# cslr_sys_001 register map
Vendor: Texas Instruments
Peripheral module from a debugger description file (folder C5505).
Address unit: 16 bits
Registers are 16-bit, access not given, reset 0x0 unless marked. A register's access mark holds for its fields unless they carry their own. Offsets are as the file gives them; lines under a group give offsets from that group; [hi:lo] are bit positions; {n}, {i} and the like mark numbered series; 'fields as' and 'values as' point back to an identical list; <NAME> marks a mode.

## SYS — The DSP system module controls several features of the DSP, e.g. clock control, DMA event synchronization, PLL settings, and the CLKOUT source.
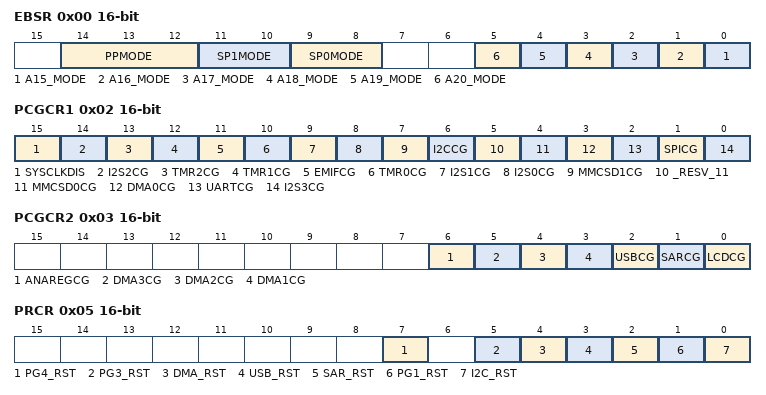
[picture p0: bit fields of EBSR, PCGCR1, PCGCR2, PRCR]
0x00 EBSR — External Bus Selection Register
  [14:12] PPMODE rw — Parallel port mode bits. These bits control the pin muxing on the parallel port.
    {v}=MODE{v} (v=0..6); 7=MODE7 (Reserved, do not use.)
  [11:10] SP1MODE rw — Serial port 1 mode bits. These bits control the pin muxing on serial port 1.
    {v}=MODE{v} (v=0..3)
  [9:8] SP0MODE rw — Serial port 0 mode bits. These bits control the pin muxing on serial port 0.
    {v}=MODE{v} (v=0..3)
  [n-15] A{n}_MODE rw (n=15..20) — This bit controls the pin multiplexing on EM_A[{n}].
    0=MODE0 (Pin behaves as EM_A[{n}].); 1=MODE1 (Pin behaves as GP[{n+6}].)
0x02 PCGCR1 — Peripheral Clock Gating Configuration Register 1
  [15] SYSCLKDIS rw — System clock disable bit. This bit can be used to turn off the system clock. Setting the WAKEUP pin high enables the system clock. Since the WAKEUP pin is used to re-enable the system clock, the WAKEUP pin must be low to disable the system clock.
    0=ACTIVE (System clock is active.); 1=DISABLED (System clock is disabled.)
  [14] I2S2CG rw — I2S2 clock gate control bit. This bit is used to enable and disable the I2S2 peripheral clock.
    0=ACTIVE (Peripheral clock is active.); 1=DISABLED (Peripheral clock is disabled.)
  [13] TMR2CG rw — Timer 2 clock gate control bit. This bit is used to enable and disable the Timer 2 peripheral clock.
    values as I2S2CG
  [12] TMR1CG rw — Timer 1 clock gate control bit. This bit is used to enable and disable the Timer 1 peripheral clock.
    values as I2S2CG
  [11] EMIFCG rw — EMIF clock gate control bit. This bit is used to enable and disable the EMIF peripheral clock. NOTE: You must request permission before stopping the EMIF clock through the peripheral clock stop request/acknowledge register (CLKSTOP).
    values as I2S2CG
  [10] TMR0CG rw — Timer 0 clock gate control bit. This bit is used to enable and disable the Timer 0 peripheral clock.
    values as I2S2CG
  [9] I2S1CG rw — I2S1 clock gate control bit. This bit is used to enable and disable the I2S1 peripheral clock.
    values as I2S2CG
  [8] I2S0CG rw — I2S0 clock gate control bit. This bit is used to enable and disable the I2S0 peripheral clock.
    values as I2S2CG
  [7] MMCSD1CG rw — MMC/SD1 clock gate control bit. This bit is used to enable and disable the MMC/SD1 peripheral clock.
    values as I2S2CG
  [6] I2CCG rw — I2C clock gate control bit. This bit is used to enable and disable the I2C peripheral clock.
    values as I2S2CG
  [5] _RESV_11 — Reserved, you must always write 1 to this bit. (access N)
  [4] MMCSD0CG rw — MMC/SD0 clock gate control bit. This bit is used to enable and disable the MMC/SD0 peripheral clock.
    values as I2S2CG
  [3] DMA0CG rw — DMA controller 0 clock gate control bit. This bit is used to enable and disable the peripheral clock the DMA controller 0.
    values as I2S2CG
  [2] UARTCG rw — UART clock gate control bit. This bit is used to enable and disable the UART peripheral clock. NOTE: You must request permission before stopping the UART clock through the peripheral clock stop request/acknowledge register (CLKSTOP).
    values as I2S2CG
  [1] SPICG rw — SPI clock gate control bit. This bit is used to enable and disable the SPI controller peripheral clock.
    values as I2S2CG
  [0] I2S3CG rw — I2S3 clock gate control bit. This bit is used to enable and disable the I2S3 peripheral clock.
    values as I2S2CG
0x03 PCGCR2 — Peripheral Clock Gating Configuration Register 2
  [6] ANAREGCG rw — Analog registers clock gate control bit. This bit is used to enable and disable the clock to the registers that control the analog domain of the device, i.e. registers in the 7000h-70FFh I/O space address range. NOTE: When SARCG = 0, the clocks to the analog domain registers is enabled regardless of the ANAREGCG setting.
    0=ACTIVE (Clock is active.); 1=DISABLED (Clock is disabled.)
  [5] DMA3CG rw — DMA controller 3 clock gate control bit. This bit is used to enable and disable the peripheral clock the DMA controller 3.
    values as PCGCR1.I2S2CG
  [4] DMA2CG rw — DMA controller 2 clock gate control bit. This bit is used to enable and disable the peripheral clock the DMA controller 2.
    values as PCGCR1.I2S2CG
  [3] DMA1CG rw — DMA controller 1 clock gate control bit. This bit is used to enable and disable the peripheral clock the DMA controller 1.
    values as PCGCR1.I2S2CG
  [2] USBCG rw — USB clock gate control bit. This bit is used to enable and disable the peripheral clock the USB. NOTE: You must request permission before stopping the USB clock through the peripheral clock stop request/acknowledge register (CLKSTOP).
    values as PCGCR1.I2S2CG
  [1] SARCG rw — SAR clock gate control bit. This bit is used to enable and disable the SAR peripheral clock. NOTE: When SARCG = 0, the clocks to the analog domain registers is enabled regardless of the ANAREGCG setting.
    values as PCGCR1.I2S2CG
  [0] LCDCG rw — LCD controller clock gate control bit. This bit is used to enable and disable the LCD controller peripheral clock.
    values as PCGCR1.I2S2CG
0x04 PSRCR rw — Peripheral Software Reset Counter Register
  [15:0] COUNT — Count bits. These bits specify the number of system clock (SYSCLK) cycles the software reset bits are asserted. When the software counter reaches 0, the software reset bits will be cleared to 0. Always initialize this field with 20h.
0x05 PRCR — Peripheral Reset Control Register
  [7] PG4_RST rw — Peripheral group 4 software reset bit. Drives the LCD, I2S2, I2S3, UART, and SPI reset signal.
    0=RST (Reset deasserted, modules out of reset.); 1=NRST (Reset asserted, modules in reset.)
  [5] PG3_RST rw — Peripheral group 3 software reset bit. Drives the MMC/SD0, MMC/SD1, I2S0, and I2S1 reset signal.
    values as PG4_RST
  [4] DMA_RST rw — DMA software reset bit. Drives the reset signal to the DMA controllers.
    values as PG4_RST
  [3] USB_RST rw — USB software reset bit. Drives the USB reset signal.
    0=RST (Reset deasserted, module out of reset.); 1=NRST (Reset asserted, module in reset.)
  [2] SAR_RST rw — Reserved. Always write 0 to these bits.
    values as USB_RST
  [1] PG1_RST rw — Peripheral group 1 software reset bit. Drives the EMIF and timers reset signal.
    values as PG4_RST
  [0] I2C_RST rw — I2C software reset bit. Drives the I2C reset signal.
    values as USB_RST
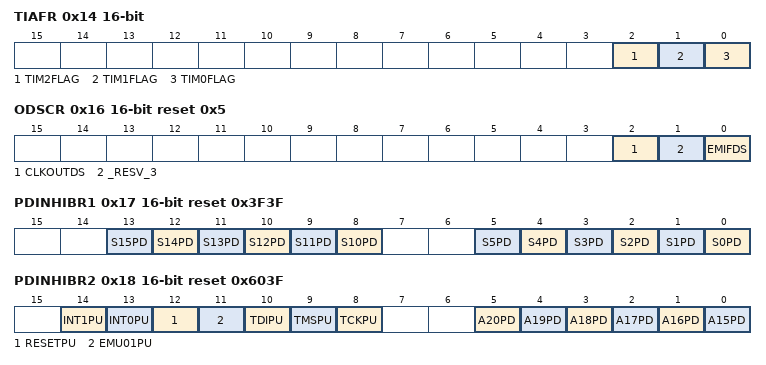
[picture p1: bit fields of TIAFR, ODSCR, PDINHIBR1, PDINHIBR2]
0x14 TIAFR — Timer Interrupt Aggregation Flag Register
  [all] fields
    0=NOINT (Timer has not generated an interrupt.); 1=INT (Timer interrupt has occurred.)
  [2] TIM2FLAG — Timer 2 interrupt flag bit. This bit latches the timer interrupt signal when the timer counter expires. You can clear this flag bit by writing a 1 to it. (access RW1C)
  [1] TIM1FLAG — Timer 1 interrupt flag bit. This bit latches the timer interrupt signal when the timer counter expires. You can clear this flag bit by writing a 1 to it. (access RW1C)
  [0] TIM0FLAG — Timer 0 interrupt flag bit. This bit latches the timer interrupt signal when the timer counter expires. You can clear this flag bit by writing a 1 to it. (access RW1C)
0x16 ODSCR reset 0x5 — Output Drive Strength Control Register
  [2] CLKOUTDS rw — CLKOUT pin output drive strength bits. These bits set the drive strength for the CLKOUT pin.
    0=MIN (Minimum drive strength.); 1=MAX (Maximum drive strength.)
  [1] _RESV_3 — (access N)
  [0] EMIFDS rw — EMIF pin output drive strength bits. These bits set the drive strength for the EMIF pins.
    values as CLKOUTDS
0x17 PDINHIBR1 reset 0x3F3F — Pull-Down Inhibit Register 1
  [all] fields
    0=ENABLE (Pin pull-down is enabled.); 1=DISABLE (Pin pull-down is disabled.)
  [n-2] S{n}PD rw (n=10..15) — Serial port pin {n} pull-down inhibit bit. Setting this bit to 1 disables the pin internal pull-down.
  [n] S{n}PD rw (n=0..5) — Serial port pin {n} pull-down inhibit bit. Setting this bit to 1 disables the pin internal pull-down.
0x18 PDINHIBR2 reset 0x603F — Pull-Down Inhibit Register 2
  [14] INT1PU rw — Interrupt 1 pin pull-up inhibit bit. Setting this bit to 1 disables the pin internal pull-up.
    0=ENABLE (Pin pull-up is enabled.); 1=DISABLE (Pin pull-up is disabled.)
  [13] INT0PU rw — Interrupt 0 pin pull-up inhibit bit. Setting this bit to 1 disables the pin internal pull-up.
    values as INT1PU
  [12] RESETPU rw — Reset pin pull-up inhibit bit. Setting this bit to 1 disables the pin internal pull-up.
    values as INT1PU
  [11] EMU01PU rw — EMU1 and EMU0 pin pull-up inhibit bit. Setting this bit to 1 disables the pin internal pull-up.
    values as INT1PU
  [10] TDIPU rw — TDI pin pull-up inhibit bit. Setting this bit to 1 disables the pin internal pull-up.
    values as INT1PU
  [9] TMSPU rw — TMS pin pull-up inhibit bit. Setting this bit to 1 disables the pin internal pull-up.
    values as INT1PU
  [8] TCKPU ro — TCK pin pull-up inhibit bit. Setting this bit to 1 disables the pin internal pull-up.
    values as INT1PU
  [n-15] A{n}PD rw (n=15..20) — EMIF A[{n}] pin pull-down inhibit bit. Setting this bit to 1 disables the pin internal pull-down.
    values as the fields of PDINHIBR1
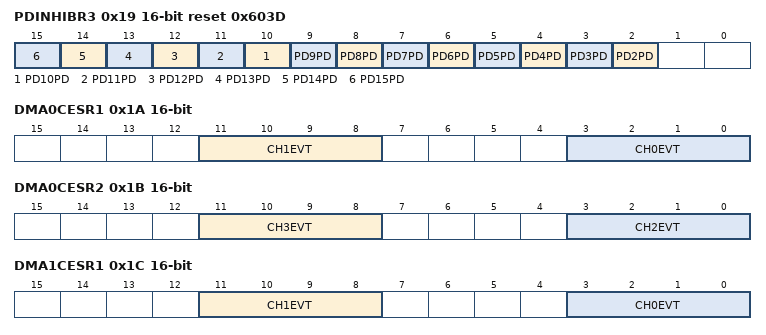
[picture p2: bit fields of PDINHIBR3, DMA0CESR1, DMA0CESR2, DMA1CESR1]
0x19 PDINHIBR3 reset 0x603D — Pull-Down Inhibit Register 3
  [all] fields
    values as the fields of PDINHIBR1
  [n] PD{n}PD rw (n=2..15) — Parallel port {n} pin pull-down inhibit bit. Setting this bit to 1 disables the pin internal pull-down.
0x1A DMA0CESR1 — Defines the synchronization events for DMA0 channel 1 and 0.
  [11:8] CH1EVT rw — Channel 1 synchronization events. When SYNCMODE = 1 in the channel DMATCR2, the CH1EVT bits in the DMAnCESR registers specify the synchronization event for activity in the DMA controller.
  [3:0] CH0EVT rw — Channel 0 synchronization events. When SYNCMODE = 1 in the channel DMATCR2, the CH0EVT bits in the DMAnCESR registers specify the synchronization event for activity in the DMA controller.
0x1B DMA0CESR2 — Defines the synchronization events for DMA0 channel 3 and 2.
  [11:8] CH3EVT rw — Channel 3 synchronization events. When SYNCMODE = 1 in the channel DMATCR2, the CH3EVT bits in the DMAnCESR registers specify the synchronization event for activity in the DMA controller.
  [3:0] CH2EVT rw — Channel 2 synchronization events. When SYNCMODE = 1 in the channel DMATCR2, the CH2EVT bits in the DMAnCESR registers specify the synchronization event for activity in the DMA controller.
0x1C DMA1CESR1 — Defines the synchronization events for DMA1 channel 1 and 0.
  fields as DMA0CESR1
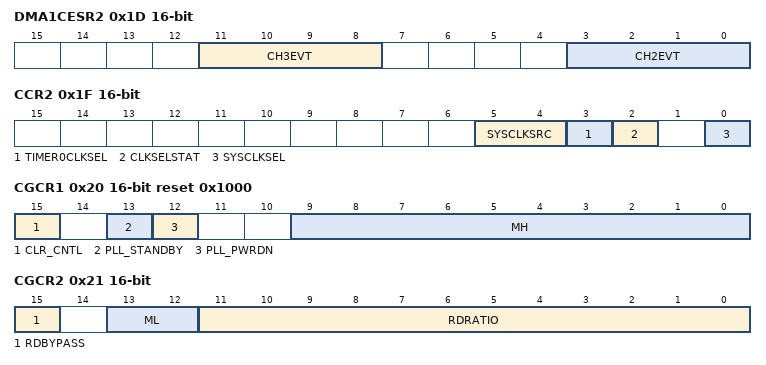
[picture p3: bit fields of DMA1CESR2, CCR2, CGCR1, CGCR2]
0x1D DMA1CESR2 — Defines the synchronization events for DMA1 channel 3 and 2.
  fields as DMA0CESR2
0x1E CCR1 — Clock Configuration Register 1
0x1E SDRAMCCR reset 0x1 — SDRAM Clock Control Register
  [0] SDCLK_EN rw — SDRAM Clock Control 0 = SDCLK on. 1 = SDCLK off.
    0=SDCLKon (SDRAM clock is on.); 1=SDCLKoff (SDRAM clock is off.)
0x1F CCR2 — Clock Configuration Register 2
  [5:4] SYSCLKSRC ro — System clock source bits. These read-only bits reflect the source for the system clock.
  [3] TIMER0CLKSEL ro — Timer0 clock source select bit. This bit specifies the input clock to Timer0.
    0=SYSCLK (Timer0 uses SYSCLK as input clock.); 1=PLLOUT (Timer0 uses PLL output clock (PLLOUT) as input clock.)
  [2] CLKSELSTAT ro — CLK_SEL pin status bit. This reflects the state of the CLK_SEL pin.
    0=RTCIN (CLK_SEL pin is low (RTC input clock selected).); 1=CLKIN (CLK_SEL pin is high (CLKIN input clock selected.))
  [0] SYSCLKSEL rw — System clock source select bit. This bit is used to select between the two main clocking modes for the DSP: bypass and lock mode. In bypass mode, the DSP clock generator is byassed and the system clock is set to either CLKIN or the RTC output (as determined by the CLKSEL pin). In lock mode, the system clock is set to the output of the DSP clock generator. Logic in the system clock generator prevents switching from bypass mode to lock mode if the PLL is powered down. After settings SYSCLKSEL = 1, you can check the SYSCLKSRC bits to determine if the system clock generator is in lock mode.
    0=BYPASS (Bypass mode is selected.); 1=LOCK (Lock mode is selected.)
0x20 CGCR1 reset 0x1000 — Clock Generator Control Register 1
  [15] CLR_CNTL rw — Clear control bit. This bit is used to clear digital flip flops within the clock generator. This bit must be cleared to 0 while changing the PLL settings.
    0=CLEAR (Digital flip-flops cleared.); 1=SET (Digital flip-flops not cleard (normal operation).)
  [13] PLL_STANDBY rw — PLL standby bit. This bit is used to place the PLL in standy mode. This bit is used for test purposes only and must always be cleared to 0.
    0=ACTIVE (PLL is active (normal operation).); 1=STANDBY (PLL is in standby mode.)
  [12] PLL_PWRDN rw — PLL power down bit. This bit is used to power down the PLL when it is not being used.
    0=POWERED (PLL is powered up.); 1=POWERDWN (PLL is powered down.)
  [9:0] MH rw — PLL multiplier value bits. These bits along with the ML bits in CGCR2 define the PLL multipler value. Multiplier value = MH x 4 + ML + 4. For example, MH = 23Bh and ML = 1h means multiply by 2289 (8F1h).
0x21 CGCR2 — Clock Generator Control Register 2
  [15] RDBYPASS rw — Reference divider bypass bit. When this bit is set to 1 the reference divider in the DSP clock generator is bypassed. When this bit is set to 0, the reference clock to the DSP clock generator is divided by the reference divider. The RD bits specify the divider value.
    0=ENABLE (Use the reference divider.); 1=BYPASS (Bypass the reference divider.)
  [13:12] ML rw — PLL multiplier value bits. These bits along with the MH bits in CGCR1 define the PLL multipler value. Multiplier value = MH x 4 + ML + 4. For example, MH = 23Bh and ML = 1h means multiply by 2289 (8F1h).
  [11:0] RDRATIO rw — Divider ratio bits for the reference divider. Divider value = RD_DIV + 4. For example, setting RD_DIV = 0 means divide by 4.
0x22 CGCR3 rw reset 0x806 — Clock Generator Control Register 3
  [15:0] INIT — Initialization bits for DSP clock generator. These bits must initialized with a pre-determined value during PLL configuration.
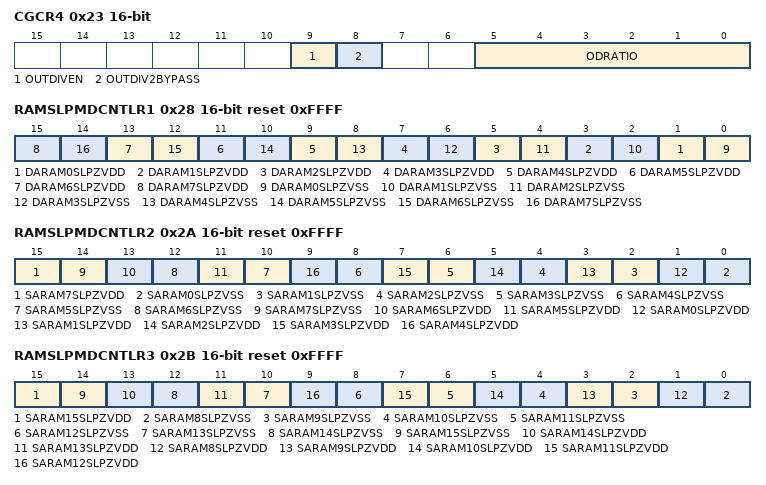
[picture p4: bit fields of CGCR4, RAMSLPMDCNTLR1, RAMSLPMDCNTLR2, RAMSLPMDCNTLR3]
0x23 CGCR4 — Clock Generator Control Register 4
  [9] OUTDIVEN rw — Output divider and fixed /2 divider enable bit. This bit determines whether the output divider and the fixed /2 divider are enabled or bypassed.
    0=BYPASS (The output divider and the fixed /2 divider are bypassed.); 1=ENABLE (The output divider and the fixed /2 divider are enabled.)
  [8] OUTDIV2BYPASS rw — Output divider bypass bit. This bit determines whether the output divider is bypassed. The fixed /2 divider is used regardless of the setting of this bit.
    0=ENABLE (The output divider is bypassed.); 1=BYPASS (The output divider is enabled.)
  [5:0] ODRATIO rw — Divider ratio bits for the output divider. Divider value = ODRATIO + 4. For example, setting ODRATIO = 2 means divide by 6. NOTE: The divider output is further divided by the fixed /2 divider.
0x24 CCSSR reset 0xB — CLKOUT Clock Source Register
  [3:0] SRC rw — CLKOUT source bits. These bits specify the source clock for the CLKOUT pin.
0x26 ECDR reset 0x1 — EMIF Clock Divider Register
  [0] EDIV rw — EMIF clock divider select bits. The EMIF module can internally divide its input peripheral clock. When this bit is set to 0, the EMIF operates at half the clock rate of its peripheral clock. When this bit is set to 1 the EMIF operates at the full rate of its peripheral clock.
    0=HALFRATE (EMIF operates at half the peripheral clock rate.); 1=FULLRATE (EMIF operates at the same rate as the peripheral clock.)
0x28 RAMSLPMDCNTLR1 rw reset 0xFFFF — RAM Sleep Mode Control Register 1
  [all] fields
    0=ENABLED; 1=DISABLED
  [2n+1] DARAM{n}SLPZVDD (n=0..7) — DARAM{n} SLPZVDD Memory Standby Enable for DARAM{n} 0 = Enable DARAM{n} SLPVDD during memory standby. 1 = Do not enable DARAM{n} SLPVDD during memory standby (normal functional mode).
  [2n] DARAM{n}SLPZVSS (n=0..7) — DARAM{n} SLPZVSS Memory Standby Enable for DARAM{n} 0 = Enable DARAM{n} SLPVSS during memory standby. 1 = Do not enable DARAM{n} SLPVSS during memory standby (normal functional mode).
0x2A RAMSLPMDCNTLR2 rw reset 0xFFFF — RAM Sleep Mode Control Register 2
  [all] fields
    0=ENABLED; 1=DISABLED
  [15] SARAM7SLPZVDD — SARAM7 SLPZVDD Memory Standby Enable for SARAM7 0 = Enable SARAM7 SLPVDD during memory standby. 1 = Do not enable SARAM7 SLPVDD during memory standby (normal functional mode).
  [2n] SARAM{n}SLPZVSS (n=0..7) — SARAM{n} SLPZVSS Memory Standby Enable for SARAM{n} 0 = Enable SARAM{n} SLPVSS during memory standby. 1 = Do not enable SARAM{n} SLPVSS during memory standby (normal functional mode).
  [13] SARAM6SLPZVDD — SARAM6 SLPZVDD Memory Standby Enable for SARAM6 0 = Enable SARAM6 SLPVDD during memory standby. 1 = Do not enable SARAM6 SLPVDD during memory standby (normal functional mode).
  [11] SARAM5SLPZVDD — DARAM5 SLPZVDD Memory Standby Enable for DARAM5 0 = Enable DARAM5 SLPVDD during memory standby. 1 = Do not enable DARAM5 SLPVDD during memory standby (normal functional mode).
  [2n+1] SARAM{n}SLPZVDD (n=0..4) — SARAM{n} SLPZVDD Memory Standby Enable for SARAM{n} 0 = Enable SARAM{n} SLPVDD during memory standby. 1 = Do not enable SARAM{n} SLPVDD during memory standby (normal functional mode).
0x2B RAMSLPMDCNTLR3 rw reset 0xFFFF — RAM Sleep Mode Control Register 3
  [all] fields
    0=ENABLED; 1=DISABLED
  [15] SARAM15SLPZVDD — SARAM15 SLPZVDD Memory Standby Enable for SARAM15 0 = Enable SARAM15 SLPVDD during memory standby. 1 = Do not enable SARAM15 SLPVDD during memory standby (normal functional mode).
  [2n-16] SARAM{n}SLPZVSS (n=8..15) — SARAM{n} SLPZVSS Memory Standby Enable for SARAM{n} 0 = Enable SARAM{n} SLPVSS during memory standby. 1 = Do not enable SARAM{n} SLPVSS during memory standby (normal functional mode).
  [13] SARAM14SLPZVDD — SARAM14 SLPZVDD Memory Standby Enable for SARAM14 0 = Enable SARAM14 SLPVDD during memory standby. 1 = Do not enable SARAM14 SLPVDD during memory standby (normal functional mode).
  [11] SARAM13SLPZVDD — DARAM13 SLPZVDD Memory Standby Enable for DARAM13 0 = Enable DARAM13 SLPVDD during memory standby. 1 = Do not enable DARAM13 SLPVDD during memory standby (normal functional mode).
  [2n-15] SARAM{n}SLPZVDD (n=8..12) — SARAM{n} SLPZVDD Memory Standby Enable for SARAM{n} 0 = Enable SARAM{n} SLPVDD during memory standby. 1 = Do not enable SARAM{n} SLPVDD during memory standby (normal functional mode).
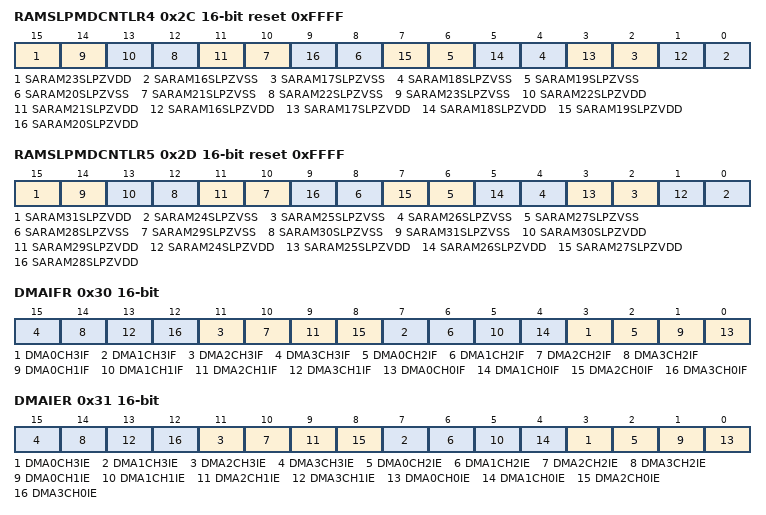
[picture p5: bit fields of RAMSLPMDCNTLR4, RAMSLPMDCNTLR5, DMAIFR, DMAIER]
0x2C RAMSLPMDCNTLR4 rw reset 0xFFFF — RAM Sleep Mode Control Register 4
  [all] fields
    0=ENABLED; 1=DISABLED
  [15] SARAM23SLPZVDD — SARAM23 SLPZVDD Memory Standby Enable for SARAM23 0 = Enable SARAM23 SLPVDD during memory standby. 1 = Do not enable SARAM23 SLPVDD during memory standby (normal functional mode).
  [2n-32] SARAM{n}SLPZVSS (n=16..23) — SARAM{n} SLPZVSS Memory Standby Enable for SARAM{n} 0 = Enable SARAM{n} SLPVSS during memory standby. 1 = Do not enable SARAM{n} SLPVSS during memory standby (normal functional mode).
  [13] SARAM22SLPZVDD — SARAM22 SLPZVDD Memory Standby Enable for SARAM22 0 = Enable SARAM22 SLPVDD during memory standby. 1 = Do not enable SARAM22 SLPVDD during memory standby (normal functional mode).
  [11] SARAM21SLPZVDD — DARAM21 SLPZVDD Memory Standby Enable for DARAM21 0 = Enable DARAM21 SLPVDD during memory standby. 1 = Do not enable DARAM21 SLPVDD during memory standby (normal functional mode).
  [2n-31] SARAM{n}SLPZVDD (n=16..20) — SARAM{n} SLPZVDD Memory Standby Enable for SARAM{n} 0 = Enable SARAM{n} SLPVDD during memory standby. 1 = Do not enable SARAM{n} SLPVDD during memory standby (normal functional mode).
0x2D RAMSLPMDCNTLR5 rw reset 0xFFFF — RAM Sleep Mode Control Register 5
  [all] fields
    0=ENABLED; 1=DISABLED
  [15] SARAM31SLPZVDD — SARAM31 SLPZVDD Memory Standby Enable for SARAM31 0 = Enable SARAM31 SLPVDD during memory standby. 1 = Do not enable SARAM31 SLPVDD during memory standby (normal functional mode).
  [2n-48] SARAM{n}SLPZVSS (n=24..31) — SARAM{n} SLPZVSS Memory Standby Enable for SARAM{n} 0 = Enable SARAM{n} SLPVSS during memory standby. 1 = Do not enable SARAM{n} SLPVSS during memory standby (normal functional mode).
  [13] SARAM30SLPZVDD — SARAM30 SLPZVDD Memory Standby Enable for SARAM30 0 = Enable SARAM30 SLPVDD during memory standby. 1 = Do not enable SARAM30 SLPVDD during memory standby (normal functional mode).
  [11] SARAM29SLPZVDD — DARAM29 SLPZVDD Memory Standby Enable for DARAM29 0 = Enable DARAM29 SLPVDD during memory standby. 1 = Do not enable DARAM29 SLPVDD during memory standby (normal functional mode).
  [2n-47] SARAM{n}SLPZVDD (n=24..28) — SARAM{n} SLPZVDD Memory Standby Enable for SARAM{n} 0 = Enable SARAM{n} SLPVDD during memory standby. 1 = Do not enable SARAM{n} SLPVDD during memory standby (normal functional mode).
0x30 DMAIFR rw — Use this register to see which DMA channels have generated interrupts.
  [all] fields
    0=CLEAR (Interrupt has not been generated.); 1=SET (Interrupt has been generated.)
  [4n+3] DMA{n}CH3IF (n=0..3) — DMA controller {n}, channel 3 interrupt status bit.
  [4n+2] DMA{n}CH2IF (n=0..3) — DMA controller {n}, channel 2 interrupt status bit.
  [4n+1] DMA{n}CH1IF (n=0..3) — DMA controller {n}, channel 1 interrupt status bit.
  [4n] DMA{n}CH0IF (n=0..3) — DMA controller {n}, channel 0 interrupt status bit.
0x31 DMAIER rw — Use this register to enabled DMA controller channel interrupts.
  [all] fields
    0=DISABLE (Interrupt is disabled.); 1=ENABLE (Interrupt is enabled.)
  [4n+3] DMA{n}CH3IE (n=0..3) — DMA controller {n}, channel 3 interrupt enable bit.
  [4n+2] DMA{n}CH2IE (n=0..3) — DMA controller {n}, channel 2 interrupt enable bit.
  [4n+1] DMA{n}CH1IE (n=0..3) — DMA controller {n}, channel 1 interrupt enable bit.
  [4n] DMA{n}CH0IE (n=0..3) — DMA controller {n}, channel 0 interrupt enable bit.
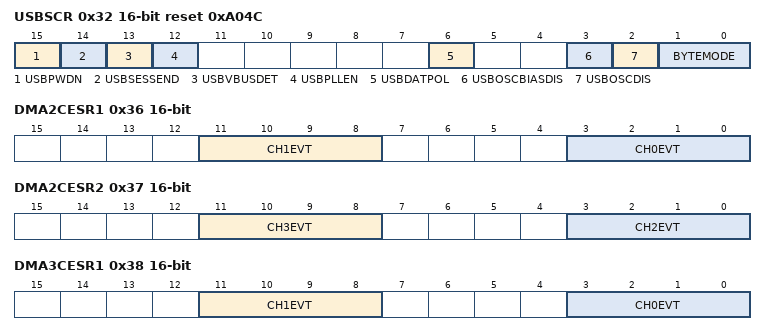
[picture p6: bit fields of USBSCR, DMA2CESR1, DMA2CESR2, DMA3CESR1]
0x32 USBSCR reset 0xA04C — USB System Control Register
  [15] USBPWDN rw — USB module power.
    0=POWERED (USB module is powered.); 1=PWRDN (USB module is powered-down.)
  [14] USBSESSEND rw — USB VBUS session end comparator enable.
    0=DISABLED (USB VBUS session end comparator is disabled.); 1=ENABLED (USB VBUS session end comparator is enabled.)
  [13] USBVBUSDET rw — USB VBUS detect enable.
    0=DISABLED (USB VBUS detect comparator is disabled.); 1=ENABLED (USB VBUS detect comparator is enabled.)
  [12] USBPLLEN rw — USB PLL enable.
    0=NORMAL (Normal USB operation.); 1=FORCEON (Override USB suspend end behavior and force release of PLL from suspend state.)
  [6] USBDATPOL rw — USB data polarity bit.
    0=REVERSE (Reverse polarity on DP and DM signals.); 1=NORMAL (Normal polarity.)
  [3] USBOSCBIASDIS rw — USB internal oscillator bias resistor disable.
    0=ENABLED (Internal oscillator bias resistor enabled (normal operating mode).); 1=DISABLED (Internal oscillator bias resistor disabled.)
  [2] USBOSCDIS rw — USB oscillator disable bit.
    0=ENABLED (USB internal oscillator enabled.); 1=DISABLED (USB internal oscillator disabled.)
  [1:0] BYTEMODE rw — USB byte mode select bits.
    0=FULL (Word accesses by the CPU are allowed.); 1=UPPER (Byte accesses by the CPU are allowed (high byte is selected).); 2=LOWER (Byte accesses by the CPU are allowed (low byte is selected).); 3=RSV (Reserved.)
0x33 ESCR — EMIF System Control Register
  [1:0] BYTEMODE rw — EMIF byte mode select bits. These bits control CPU data and program accesses to external memory as well as CPU accesses the EMIF memory-mapped registers.
    values as USBSCR.BYTEMODE
0x36 DMA2CESR1 — Defines the synchronization events for DMA2 channel 1 and 0.
  fields as DMA0CESR1
0x37 DMA2CESR2 — Defines the synchronization events for DMA2 channel 3 and 2.
  fields as DMA0CESR2
0x38 DMA3CESR1 — Defines the synchronization events for DMA3 channel 1 and 0.
  fields as DMA0CESR1
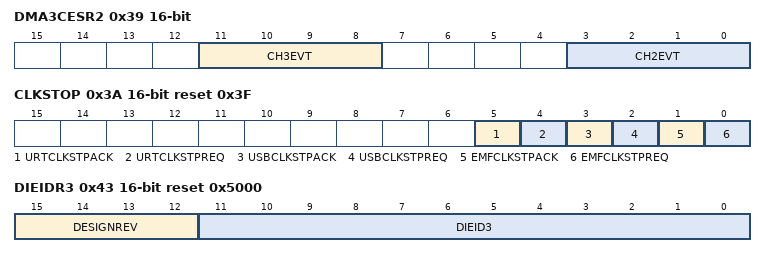
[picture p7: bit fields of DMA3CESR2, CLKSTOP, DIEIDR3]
0x39 DMA3CESR2 — Defines the synchronization events for DMA3 channel 3 and 2.
  fields as DMA0CESR2
0x3A CLKSTOP reset 0x3F — Peripheral Clock Stop Request/Acknowledge Register
  [5] URTCLKSTPACK ro — UART clock stop acknowledge bit. This bit is set to 1 when the UART has acknowledged a request for its clock to be stopped. The UART clock should not be stopped until this bit is set to 1.
    0=NACK (The request to stop the peripheral clock has not been acknowledged.); 1=ACK (The request to stop the peripheral clock has been acknowledged, the clock can be stopped.)
  [4] URTCLKSTPREQ rw — UART peripheral clock stop request bit. When disabling the UART internal peripheral clock, you must set this bit to 1 to request permission to stop the clock. After the UART acknowledges the request (URTCLKSTPACK = 1) you can stop the clock through the peripheral clock gating control register 1 (PCGCR1). When enabling the UART internal clock, enable the clock through PCGCR1, then set URTCKLSTPREQ to 0.
    0=NREQ (Normal operating mode.); 1=REQ (Request permission to stop the peripheral clock.)
  [3] USBCLKSTPACK ro — USB clock stop acknowledge bit. This bit is set to 1 when the USB has acknowledged a request for its clock to be stopped. The USB clock should not be stopped until this bit is set to 1.
    values as URTCLKSTPACK
  [2] USBCLKSTPREQ rw — USB peripheral clock stop request bit. When disabling the USB internal peripheral clock, you must set this bit to 1 to request permission to stop the clock. After the USB acknowledges the request (USBCLKSTPACK = 1) you can stop the clock through the peripheral clock gating control register 2 (PCGCR2). When enabling the USB internal clock, enable the clock through PCGCR2, then set USBCKLSTPREQ to 0.
    values as URTCLKSTPREQ
  [1] EMFCLKSTPACK ro — EMIF clock stop acknowledge bit. This bit is set to 1 when the EMIF has acknowledged a request for its clock to be stopped. The EMIF clock should not be stopped until this bit is set to 1.
    values as URTCLKSTPACK
  [0] EMFCLKSTPREQ rw — EMIF peripheral clock stop request bit. When disabling the EMIF internal peripheral clock, you must set this bit to 1 to request permission to stop the clock. After the EMIF acknowledges the request (EMFCLKSTPACK = 1) you can stop the clock through the peripheral clock gating control register 1 (PCGCR1). When enabling the EMIF internal clock, enable the clock through PCGCR1, then set EMFCKLSTPREQ to 0.
    values as URTCLKSTPREQ
0x40 DIEIDR0 ro — Die ID Register 0
  [15:0] DIEID0 — Die ID bits.
0x41 DIEIDR1 — Die ID Register 1
  [13:0] DIEID1 ro — Die ID bits.
0x42 DIEIDR2 ro — Die ID Register 2
  [15:0] DIEID2 — Die ID bits.
0x43 DIEIDR3 ro reset 0x5000 — Die ID Register 3
  [15:12] DESIGNREV — Describes the Silicon Revision of Die CPU 0 = Silicon Revision 1.0. 1 = Silicon Revision 1.1. 2 = Silicon Revision 1.2. 3 = Silicon Revision 1.3. 4 = Silicon Revision 1.4. 5 = Silicon Revision 2.0.
  [11:0] DIEID3 — Die ID bits.
0x44 DIEIDR4 — Die ID Register 4
  [5:0] DIEID4 ro — Die ID bits.
0x45 DIEIDR5 — Die ID Register 5
0x46 DIEIDR6 — Die ID Register 6
0x47 DIEIDR7 — Die ID Register 7
  [14:1] CHECKSUM ro — Checksum bits.
